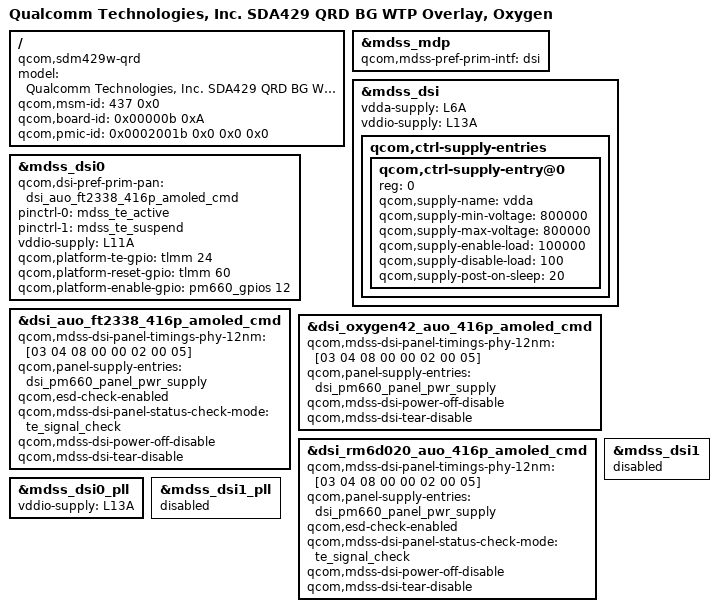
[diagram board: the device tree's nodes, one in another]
/*
 * Copyright (c) 2020, The Linux Foundation. All rights reserved.
 *
 * This program is free software; you can redistribute it and/or modify
 * it under the terms of the GNU General Public License version 2 and
 * only version 2 as published by the Free Software Foundation.
 *
 * This program is distributed in the hope that it will be useful,
 * but WITHOUT ANY WARRANTY; without even the implied warranty of
 * MERCHANTABILITY or FITNESS FOR A PARTICULAR PURPOSE.  See the
 * GNU General Public License for more details.
 */

/dts-v1/;
/plugin/;

#include <dt-bindings/clock/qcom,rpmcc.h>
#include "sda429-bg-dvt2-wtp.dtsi"
#include "sdm429-mdss-panels.dtsi"
#include "sdm429-spyro-qrd-evt-audio.dtsi"
#include "custom-overlay-tp.dtsi"
#include "custom-overlay-key.dtsi"
#include "custom-overlay-vibrator.dtsi"
#include "custom-overlay-aw8624-haptics.dtsi"
#include "custom-overlay-audio.dtsi"
#include "custom-overlay-lcd-auo-ft2338-416p-amoled-cmd.dtsi"
#include "custom-overlay-lcd-auo-oxygen42-416p-amoled-cmd.dtsi"
#include "custom-overlay-lcd-auo-rm6d020-416p-amoled-cmd.dtsi"
#include "custom-overlay-charge.dtsi"

/ {
	model = "Qualcomm Technologies, Inc. SDA429 QRD BG WTP Overlay, Oxygen";
	compatible = "qcom,sdm429w-qrd", "qcom,sdm429w", "qcom,qrd";
	qcom,msm-id = <437 0x0>;
	qcom,board-id = <0x00000b 0xA>;
	qcom,pmic-id = <0x0002001b 0x0 0x0 0x0>;
};

&mdss_mdp {
	qcom,mdss-pref-prim-intf = "dsi";
};

&mdss_dsi {
	/delete-property/ vdda-supply;
	/delete-property/ vddio-supply;
	vdda-supply = <&L6A>; /* 0.8v */
	vddio-supply = <&L13A>; /* 1.8v */

	qcom,ctrl-supply-entries {
		#address-cells = <1>;
		#size-cells = <0>;

		qcom,ctrl-supply-entry@0 {
			reg = <0>;
			qcom,supply-name = "vdda";
			qcom,supply-min-voltage = <800000>;
			qcom,supply-max-voltage = <800000>;
			qcom,supply-enable-load = <100000>;
			qcom,supply-disable-load = <100>;
			qcom,supply-post-on-sleep = <20>;
		};
	};
};

&mdss_dsi0 {
	/delete-property/ vdd-supply;
	qcom,dsi-pref-prim-pan = <&dsi_auo_ft2338_416p_amoled_cmd>;
	pinctrl-names = "mdss_default", "mdss_sleep";
	pinctrl-0 = <&mdss_te_active>;
	pinctrl-1 = <&mdss_te_suspend>;
	vddio-supply = <&L11A>;
	qcom,platform-te-gpio = <&tlmm 24 0>;
	qcom,platform-reset-gpio = <&tlmm 60 0>;
	qcom,platform-enable-gpio = <&pm660_gpios 12 0>;

};

&dsi_auo_ft2338_416p_amoled_cmd {
        /delete-property/ qcom,mdss-dsi-panel-timings;
        qcom,mdss-dsi-panel-timings-phy-12nm = [03 04 08 00 00 02 00 05];
        qcom,panel-supply-entries = <&dsi_pm660_panel_pwr_supply>;
        qcom,esd-check-enabled;
        qcom,mdss-dsi-panel-status-check-mode = "te_signal_check";
        qcom,mdss-dsi-power-off-disable;
        qcom,mdss-dsi-tear-disable;
        /delete-property/ qcom,mdss-skip-panel-reset;
};

&dsi_oxygen42_auo_416p_amoled_cmd {
        /delete-property/ qcom,mdss-dsi-panel-timings;
        qcom,mdss-dsi-panel-timings-phy-12nm = [03 04 08 00 00 02 00 05];
        qcom,panel-supply-entries = <&dsi_pm660_panel_pwr_supply>;
        // qcom,esd-check-enabled;
        // qcom,mdss-dsi-panel-status-check-mode = "te_signal_check";
        qcom,mdss-dsi-power-off-disable;
        qcom,mdss-dsi-tear-disable;
        /delete-property/ qcom,mdss-skip-panel-reset;
};

&dsi_rm6d020_auo_416p_amoled_cmd {
        /delete-property/ qcom,mdss-dsi-panel-timings;
        qcom,mdss-dsi-panel-timings-phy-12nm = [03 04 08 00 00 02 00 05];
        qcom,panel-supply-entries = <&dsi_pm660_panel_pwr_supply>;
        qcom,esd-check-enabled;
        qcom,mdss-dsi-panel-status-check-mode = "te_signal_check";
        qcom,mdss-dsi-power-off-disable;
        qcom,mdss-dsi-tear-disable;
        /delete-property/ qcom,mdss-skip-panel-reset;
};

&mdss_dsi0_pll {
	/delete-property/ vddio-supply;
	vddio-supply = <&L13A>;
};

&mdss_dsi1 {
	status = "disabled";
};

&mdss_dsi1_pll {
	status = "disabled";
};

